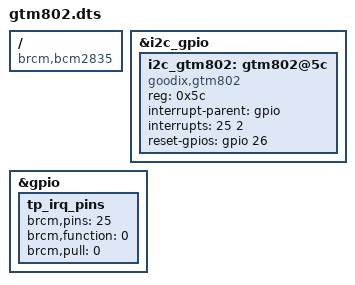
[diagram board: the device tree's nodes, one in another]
/dts-v1/;
/plugin/;

/{
    compatible = "brcm,bcm2835", "brcm,bcm2708", "brcm,bcm2709";

    fragment@0 {
        target = <&i2c_gpio>;
        __overlay__{
            #address-cells = <1>;
            #size-cells = <0>;
            i2c_gtm802: gtm802@5c {
                compatible = "goodix,gtm802";
                reg = <0x5c>;
                interrupt-parent = <&gpio>;
                interrupts = <25 2>;
                reset-gpios = <&gpio 26 0>;
            };
        };
    };

	fragment@1 {
		target = <&gpio>;
		__overlay__ {
			tp_irq_pins: tp_irq_pins {
				brcm,pins = <25>;
				brcm,function = <0>; /* in */
				brcm,pull = <0>; /* none */
			};
		};
	};

};
